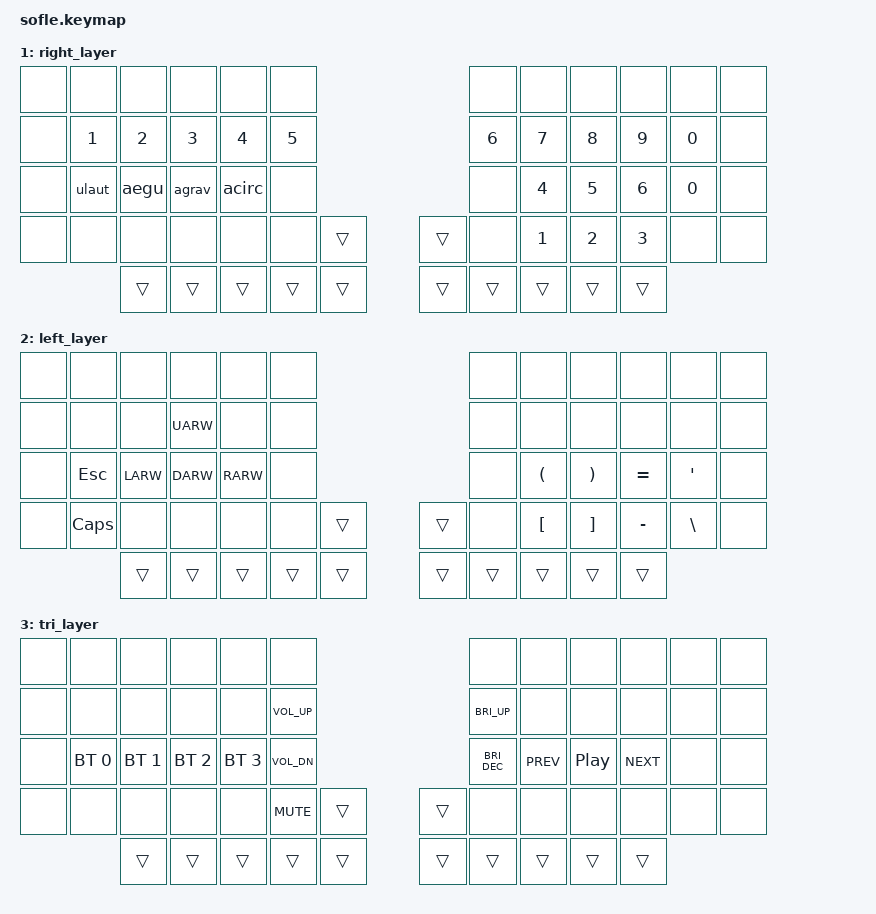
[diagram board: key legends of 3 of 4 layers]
/*
 * Copyright (c) 2020 The ZMK Contributors
 *
 * SPDX-License-Identifier: MIT
 */

#include <behaviors.dtsi>
#include <dt-bindings/zmk/keys.h>
#include <dt-bindings/zmk/bt.h>

#define HRML(k2,k3,k4) &ht LCTRL k2  &ht LALT k3  &ht LGUI k4
#define HRMR(k1,k2,k3) &ht RGUI k1  &ht RALT k2  &ht RCTRL k3

#define CMK 0
#define RIG 1
#define LEF 2
#define TRI 3

/ {
macros {
	ulaut: ulaut {
		label = "Umlaut";
		compatible = "zmk,behavior-macro";
		#binding-cells = <0>;
		bindings
                	= <&macro_press &kp LALT>
                	, <&macro_tap &kp U>
                	, <&macro_release &kp LALT>
                	;
        };

	agrav: agrav {
		label = "AGrav";
		compatible = "zmk,behavior-macro";
		#binding-cells = <0>;
		bindings
			= <&macro_press &kp LALT>
			, <&macro_tap &kp GRAVE>
			, <&macro_release &kp LALT>
			;
        };

	aegu: aegu {
		label = "AEgu";
		compatible = "zmk,behavior-macro";
		#binding-cells = <0>;
		bindings
			= <&macro_press &kp LALT>
			, <&macro_tap &kp E>
			, <&macro_release &kp LALT>
			;
        };

	acirc: acirc {
		label = "ACirc";
		compatible = "zmk,behavior-macro";
		#binding-cells = <0>;
		bindings
			= <&macro_press &kp LALT>
			, <&macro_tap &kp I>
			, <&macro_release &kp LALT>
			;
        };
    };
behaviors {
        ht: hold_tap {
            label = "hold_tap";
            compatible = "zmk,behavior-hold-tap";
            #binding-cells = <2>;
            flavor = "tap-preferred";
            tapping-term-ms = <220>;
            quick-tap-ms = <150>;
            global-quick-tap;
            bindings = <&kp>, <&kp>;
        };
    };

    conditional_layers {
        compatible = "zmk,conditional-layers";
        tri_layer {
            if-layers = <RIG LEF>;
            then-layer = <TRI>;
        };
    };

keymap {
	compatible = "zmk,keymap";

        default_layer {
            bindings = <
&none   &none  &none     &none     &none     &none                                     &none        &none      &none     &none    &none    &none
&none   &kp Q  &kp W     &kp F     &kp P     &kp G                                     &kp J        &kp L      &kp U     &kp Y    &kp SEMI &none
&none   &kp A  HRML(R,       S,       T)     &kp D                                     &kp H        HRMR(N,       E,        I)    &kp O    &none
&none   &kp Z  &kp X     &kp C     &kp V     &kp B               &kp C_PP   &none      &kp K        &kp M      &kp COMMA &kp DOT  &kp FSLH &none
               &none    &none     &lt LEF TAB  &mt LSHIFT BSPC   &none      &none      &kp SPACE    &lt RIG ENTER &none   &kp ESC
            >;

            sensor-bindings = <&inc_dec_kp C_VOL_DN C_VOL_UP &inc_dec_kp PG_DN PG_UP>;
        };

        right_layer {
            bindings = <
&none         &none         &none         &none         &none         &none                                 &none      &none     &none     &none     &none     &none
&none         &kp N1        &kp N2        &kp N3        &kp N4        &kp N5                                &kp N6     &kp N7    &kp N8    &kp N9    &kp N0    &none
&none         &ulaut        &aegu         &agrav        &acirc        &none                                 &none      &kp N4    &kp N5    &kp N6    &kp N0    &none
&none         &none         &none         &none         &none         &none        &trans       &trans      &none      &kp N1    &kp N2    &kp N3    &none     &none
&trans        &trans        &trans        &trans        &trans       &trans        &trans       &trans      &trans     &trans
            >;

            sensor-bindings = <&inc_dec_kp C_VOL_DN C_VOL_UP &inc_dec_kp PG_DN PG_UP>;
        };

	left_layer {
            bindings = <
&none         &none         &none         &none         &none         &none                                 &none      &none     &none      &none      &none      &none
&none         &none         &none         &kp UARW      &none         &none                                 &none      &none     &none      &none      &none      &none
&none         &kp ESC       &kp LARW      &kp DARW      &kp RARW      &none                                 &none      &kp LPAR  &kp RPAR   &kp EQUAL  &kp SQT    &none
&none         &kp CAPS      &none         &none         &none         &none        &trans       &trans      &none      &kp LBKT  &kp RBKT   &kp MINUS  &kp BSLH   &none
&trans        &trans        &trans        &trans        &trans        &trans       &trans       &trans      &trans     &trans
            >;

            sensor-bindings = <&inc_dec_kp C_VOL_DN C_VOL_UP &inc_dec_kp PG_DN PG_UP>;
        };

	tri_layer {
            bindings = <
&none         &none         &none         &none         &none         &none                                 &none         &none     &none      &none      &none      &none
&none         &none         &none         &none         &none         &kp C_VOL_UP                          &kp C_BRI_UP  &none     &none      &none      &none      &none
&none         &bt BT_SEL 0  &bt BT_SEL 1  &bt BT_SEL 2  &bt BT_SEL 3  &kp C_VOL_DN                          &kp C_BRI_DEC &kp C_PREV &kp C_PP  &kp C_NEXT &none      &none
&none         &none         &none         &none         &none         &kp C_MUTE   &trans       &trans      &none         &none     &none      &none      &none      &none
&trans        &trans        &trans        &trans        &trans        &trans       &trans       &trans      &trans        &trans
            >;

            sensor-bindings = <&inc_dec_kp C_VOL_DN C_VOL_UP &inc_dec_kp PG_DN PG_UP>;
        };
    };
};
